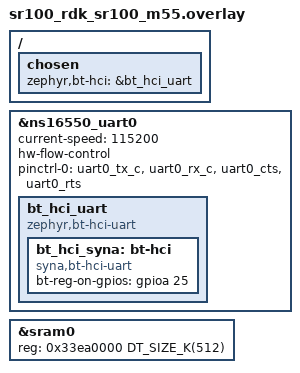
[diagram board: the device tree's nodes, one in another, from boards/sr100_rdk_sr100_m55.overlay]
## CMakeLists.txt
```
# Copyright (c) 2026 Synaptics Incorporated
#
# SPDX-License-Identifier: Apache-2.0

cmake_minimum_required(VERSION 3.20.0)

set(LIBSBC_MODULE_PATH "$ENV{ZEPHYR_BASE}/../modules/lib/libsbc")
if(EXISTS "${LIBSBC_MODULE_PATH}/zephyr/module.yml")
  list(APPEND ZEPHYR_EXTRA_MODULES "${LIBSBC_MODULE_PATH}")
endif()

find_package(Zephyr REQUIRED HINTS $ENV{ZEPHYR_BASE})
project(classic_a2dp_sink)

target_sources(app PRIVATE
  src/main.c
)
```

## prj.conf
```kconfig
CONFIG_BT=y
CONFIG_LOG=y
CONFIG_BT_CLASSIC=y
CONFIG_BT_AVDTP=y
CONFIG_BT_A2DP=y
CONFIG_BT_A2DP_SINK=y
CONFIG_LIBSBC=y
CONFIG_BT_CONN_TX_MAX=15
CONFIG_BT_DEVICE_NAME="SR110 A2DP Sink"
CONFIG_BT_COD=0x200404
CONFIG_BT_DID=y
CONFIG_BT_DEVICE_VEDNOR_ID=0x0000
CONFIG_BT_DEVICE_PRODUCT_ID=0x0001
CONFIG_BT_DEVICE_VERSION=0x0001
CONFIG_BT_BUF_ACL_RX_SIZE=1024

# SR110 + SYNA hardware
CONFIG_BT_H4=y
CONFIG_BT_HCI_SYNA=y
CONFIG_BT_HCI_SYNA_BAUD_RATE=1500000
CONFIG_GPIO=y
CONFIG_UART_INTERRUPT_DRIVEN=y
CONFIG_UART_NS16550_VARIANT_NS16750=y
CONFIG_SRAM_SIZE=512
CONFIG_MAIN_STACK_SIZE=3072
CONFIG_BT_RX_STACK_SIZE=3072
CONFIG_BT_BUF_CMD_TX_SIZE=255
CONFIG_BT_AVDTP_LOG_LEVEL_DBG=y
CONFIG_BT_A2DP_LOG_LEVEL_DBG=y
CONFIG_BT_L2CAP_LOG_LEVEL_DBG=y
CONFIG_BT_SDP_LOG_LEVEL_DBG=y
CONFIG_BT_CONN_LOG_LEVEL_INF=y
CONFIG_BT_HCI_ACL_FLOW_CONTROL=n
CONFIG_BT_HCI_CORE_LOG_LEVEL_INF=y
CONFIG_LOG_PRINTK=n

# Disable unsupported features
CONFIG_SHELL=n
CONFIG_MBEDTLS_PSA_CRYPTO_C=n
CONFIG_XIP=n
```

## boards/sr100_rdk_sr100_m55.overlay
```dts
/*
 * Copyright (c) 2026 Synaptics Incorporated
 *
 * SPDX-License-Identifier: Apache-2.0
 */

/ {
	chosen {
		zephyr,bt-hci = &bt_hci_uart;
	};
};

&ns16550_uart0 {
	status = "okay";
	current-speed = <115200>;
	hw-flow-control;
	pinctrl-0 = <&uart0_tx_c &uart0_rx_c &uart0_cts &uart0_rts>;
	pinctrl-names = "default";

	bt_hci_uart: bt_hci_uart {
		compatible = "zephyr,bt-hci-uart";
		status = "okay";

		bt_hci_syna: bt-hci {
			compatible = "syna,bt-hci-uart";
			status = "okay";
			bt-reg-on-gpios = <&gpioa 25 GPIO_ACTIVE_HIGH>;
		};
	};
};

/* Extend SRAM for BT host stack + patchram (512K needed for Classic BT + A2DP) */
&sram0 {
	reg = <0x33ea0000 DT_SIZE_K(512)>;
	ranges = <0x0 0x33ea0000 DT_SIZE_K(512)>;
};
```

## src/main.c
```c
/*
 * Copyright (c) 2026 Synaptics Incorporated
 *
 * SPDX-License-Identifier: Apache-2.0
 */

#include <zephyr/kernel.h>
#include <zephyr/bluetooth/bluetooth.h>
#include <zephyr/bluetooth/addr.h>
#include <zephyr/bluetooth/conn.h>
#include <zephyr/bluetooth/classic/classic.h>
#include <zephyr/bluetooth/classic/a2dp.h>
#include <zephyr/bluetooth/classic/a2dp_codec_sbc.h>
#include <zephyr/bluetooth/classic/sdp.h>
#include <zephyr/logging/log.h>

LOG_MODULE_REGISTER(a2dp_sink);

#define A2DP_VERSION 0x0103

static struct bt_a2dp *default_a2dp;
BT_A2DP_SBC_SINK_EP_DEFAULT(sbc_sink_ep);
static struct bt_a2dp_stream sbc_stream;

static struct bt_sdp_attribute a2dp_sink_attrs[] = {
	BT_SDP_NEW_SERVICE,
	BT_SDP_LIST(
		BT_SDP_ATTR_SVCLASS_ID_LIST,
		BT_SDP_TYPE_SIZE_VAR(BT_SDP_SEQ8, 3),
		BT_SDP_DATA_ELEM_LIST({
			BT_SDP_TYPE_SIZE(BT_SDP_UUID16),
			BT_SDP_ARRAY_16(BT_SDP_AUDIO_SINK_SVCLASS)
		}, )
	),
	BT_SDP_LIST(
		BT_SDP_ATTR_PROFILE_DESC_LIST,
		BT_SDP_TYPE_SIZE_VAR(BT_SDP_SEQ8, 8),
		BT_SDP_DATA_ELEM_LIST({
			BT_SDP_TYPE_SIZE_VAR(BT_SDP_SEQ8, 6),
			BT_SDP_DATA_ELEM_LIST({
				BT_SDP_TYPE_SIZE(BT_SDP_UUID16),
				BT_SDP_ARRAY_16(BT_SDP_ADVANCED_AUDIO_SVCLASS)
			},
			{
				BT_SDP_TYPE_SIZE(BT_SDP_UINT16),
				BT_SDP_ARRAY_16(A2DP_VERSION)
			}, )
		}, )
	),
	BT_SDP_SUPPORTED_FEATURES(0x0001U),
};

static struct bt_sdp_record a2dp_sink_rec = BT_SDP_RECORD(a2dp_sink_attrs);

static const char *br_addr_str(struct bt_conn *conn, char *buf, size_t len)
{
	const bt_addr_t *addr = bt_conn_get_dst_br(conn);

	if (addr == NULL) {
		snprintk(buf, len, "<unknown>");
		return buf;
	}

	(void)bt_addr_to_str(addr, buf, len);
	return buf;
}

static void sbc_stream_configured(struct bt_a2dp_stream *stream)
{
	ARG_UNUSED(stream);
	LOG_INF("A2DP stream configured");
}

static void sbc_stream_established(struct bt_a2dp_stream *stream)
{
	ARG_UNUSED(stream);
	LOG_INF("A2DP stream established");
}

static void sbc_stream_released(struct bt_a2dp_stream *stream)
{
	ARG_UNUSED(stream);
	LOG_INF("A2DP stream released");
}

static void sbc_stream_started(struct bt_a2dp_stream *stream)
{
	ARG_UNUSED(stream);
	LOG_INF("A2DP stream started - receiving audio data");
}

static void sbc_stream_suspended(struct bt_a2dp_stream *stream)
{
	ARG_UNUSED(stream);
	LOG_INF("A2DP stream suspended");
}

static void sbc_stream_recv(struct bt_a2dp_stream *stream, struct net_buf *buf, uint16_t seq_num,
			    uint32_t ts)
{
	ARG_UNUSED(stream);
	ARG_UNUSED(seq_num);
	ARG_UNUSED(ts);

	LOG_DBG("Received SBC frame: %d bytes, seq=%u, ts=%u", buf->len, seq_num, ts);
	net_buf_pull(buf, buf->len);
}

static struct bt_a2dp_stream_ops stream_ops = {
	.configured = sbc_stream_configured,
	.established = sbc_stream_established,
	.released = sbc_stream_released,
	.started = sbc_stream_started,
	.suspended = sbc_stream_suspended,
	.recv = sbc_stream_recv,
};

static void app_a2dp_connected(struct bt_a2dp *a2dp, int err)
{
	if (err == 0) {
		default_a2dp = a2dp;
		LOG_INF("A2DP signaling connected - waiting for Source to initiate stream");
	} else {
		LOG_WRN("A2DP signaling connect failed (%d)", err);
	}
}

static void app_a2dp_disconnected(struct bt_a2dp *a2dp)
{
	ARG_UNUSED(a2dp);
	default_a2dp = NULL;
	LOG_INF("A2DP signaling disconnected");
}

static int app_a2dp_config_req(struct bt_a2dp *a2dp, struct bt_a2dp_ep *ep,
			       struct bt_a2dp_codec_cfg *codec_cfg, struct bt_a2dp_stream **stream,
			       uint8_t *rsp_err_code)
{
	ARG_UNUSED(a2dp);
	ARG_UNUSED(ep);
	ARG_UNUSED(codec_cfg);

	bt_a2dp_stream_cb_register(&sbc_stream, &stream_ops);
	*stream = &sbc_stream;
	*rsp_err_code = 0;
	LOG_INF("A2DP config request accepted");

	return 0;
}

static int app_a2dp_establish_req(struct bt_a2dp_stream *stream, uint8_t *rsp_err_code)
{
	ARG_UNUSED(stream);
	*rsp_err_code = 0;
	LOG_INF("A2DP establish request accepted");
	return 0;
}

static int app_a2dp_start_req(struct bt_a2dp_stream *stream, uint8_t *rsp_err_code)
{
	ARG_UNUSED(stream);
	*rsp_err_code = 0;
	LOG_INF("A2DP start request accepted");
	return 0;
}

static int app_a2dp_suspend_req(struct bt_a2dp_stream *stream, uint8_t *rsp_err_code)
{
	ARG_UNUSED(stream);
	*rsp_err_code = 0;
	LOG_INF("A2DP suspend request accepted");
	return 0;
}

static int app_a2dp_release_req(struct bt_a2dp_stream *stream, uint8_t *rsp_err_code)
{
	ARG_UNUSED(stream);
	*rsp_err_code = 0;
	LOG_INF("A2DP release request accepted");
	return 0;
}

static int app_a2dp_abort_req(struct bt_a2dp_stream *stream, uint8_t *rsp_err_code)
{
	ARG_UNUSED(stream);
	*rsp_err_code = 0;
	LOG_INF("A2DP abort request accepted");
	return 0;
}

static void app_a2dp_config_rsp(struct bt_a2dp_stream *stream, uint8_t rsp_err_code)
{
	ARG_UNUSED(stream);
	LOG_INF("A2DP config response err=0x%02x", rsp_err_code);
}

static void app_a2dp_establish_rsp(struct bt_a2dp_stream *stream, uint8_t rsp_err_code)
{
	ARG_UNUSED(stream);
	LOG_INF("A2DP establish response err=0x%02x", rsp_err_code);
}

static void app_a2dp_start_rsp(struct bt_a2dp_stream *stream, uint8_t rsp_err_code)
{
	ARG_UNUSED(stream);
	LOG_INF("A2DP start response err=0x%02x", rsp_err_code);
}

static void app_a2dp_suspend_rsp(struct bt_a2dp_stream *stream, uint8_t rsp_err_code)
{
	ARG_UNUSED(stream);
	LOG_INF("A2DP suspend response err=0x%02x", rsp_err_code);
}

static void app_a2dp_release_rsp(struct bt_a2dp_stream *stream, uint8_t rsp_err_code)
{
	ARG_UNUSED(stream);
	LOG_INF("A2DP release response err=0x%02x", rsp_err_code);
}

static void app_a2dp_abort_rsp(struct bt_a2dp_stream *stream, uint8_t rsp_err_code)
{
	ARG_UNUSED(stream);
	LOG_INF("A2DP abort response err=0x%02x", rsp_err_code);
}

static struct bt_a2dp_cb a2dp_cb = {
	.connected = app_a2dp_connected,
	.disconnected = app_a2dp_disconnected,
	.config_req = app_a2dp_config_req,
	.establish_req = app_a2dp_establish_req,
	.start_req = app_a2dp_start_req,
	.suspend_req = app_a2dp_suspend_req,
	.release_req = app_a2dp_release_req,
	.abort_req = app_a2dp_abort_req,
	.config_rsp = app_a2dp_config_rsp,
	.establish_rsp = app_a2dp_establish_rsp,
	.start_rsp = app_a2dp_start_rsp,
	.suspend_rsp = app_a2dp_suspend_rsp,
	.release_rsp = app_a2dp_release_rsp,
	.abort_rsp = app_a2dp_abort_rsp,
};

static void br_conn_connected(struct bt_conn *conn, uint8_t err)
{
	char addr[BT_ADDR_STR_LEN];

	if (!bt_conn_is_type(conn, BT_CONN_TYPE_BR)) {
		return;
	}

	if (err != 0U) {
		LOG_WRN("BR/EDR ACL connect failed (%u), peer %s", err,
			br_addr_str(conn, addr, sizeof(addr)));
		return;
	}

	LOG_INF("BR/EDR ACL connected: %s", br_addr_str(conn, addr, sizeof(addr)));
}

static void br_conn_disconnected(struct bt_conn *conn, uint8_t reason)
{
	char addr[BT_ADDR_STR_LEN];

	if (!bt_conn_is_type(conn, BT_CONN_TYPE_BR)) {
		return;
	}

	LOG_INF("BR/EDR ACL disconnected: %s (reason 0x%02x)",
		br_addr_str(conn, addr, sizeof(addr)), reason);
}

static void br_conn_security_changed(struct bt_conn *conn, bt_security_t level,
				     enum bt_security_err err)
{
	char addr[BT_ADDR_STR_LEN];

	if (!bt_conn_is_type(conn, BT_CONN_TYPE_BR)) {
		return;
	}

	LOG_INF("BR/EDR security changed: %s level %u err %d",
		br_addr_str(conn, addr, sizeof(addr)), level, err);

	LOG_INF("Waiting for A2DP Source to initiate AVDTP signaling");
}

static struct bt_conn_cb conn_cb = {
	.connected = br_conn_connected,
	.disconnected = br_conn_disconnected,
	.security_changed = br_conn_security_changed,
};

static void auth_pairing_complete(struct bt_conn *conn, bool bonded)
{
	char addr[BT_ADDR_STR_LEN];

	if (!bt_conn_is_type(conn, BT_CONN_TYPE_BR)) {
		return;
	}

	LOG_INF("Pairing complete: %s bonded=%d", br_addr_str(conn, addr, sizeof(addr)), bonded);
}

static void auth_pairing_failed(struct bt_conn *conn, enum bt_security_err reason)
{
	char addr[BT_ADDR_STR_LEN];

	if (!bt_conn_is_type(conn, BT_CONN_TYPE_BR)) {
		return;
	}

	LOG_WRN("Pairing failed: %s reason=%d", br_addr_str(conn, addr, sizeof(addr)), reason);
}

static struct bt_conn_auth_info_cb auth_info_cb = {
	.pairing_complete = auth_pairing_complete,
	.pairing_failed = auth_pairing_failed,
};

static int bt_ready(void)
{
	int err;

	err = bt_enable(NULL);
	if (err) {
		LOG_ERR("Bluetooth init failed (err %d)", err);
		return err;
	}

	LOG_INF("Bluetooth enabled");

	{
		bt_addr_le_t addrs[CONFIG_BT_ID_MAX];
		size_t count = ARRAY_SIZE(addrs);
		char addr_str[BT_ADDR_LE_STR_LEN];

		bt_id_get(addrs, &count);
		if (count > 0) {
			bt_addr_le_to_str(&addrs[0], addr_str, sizeof(addr_str));
			LOG_INF("Local BD_ADDR: %s", addr_str);
		}
	}

	bt_conn_cb_register(&conn_cb);
	bt_conn_auth_info_cb_register(&auth_info_cb);
	LOG_INF("Connection diagnostic callbacks registered");

	bt_sdp_register_service(&a2dp_sink_rec);
	LOG_INF("A2DP SDP record registered");

	err = bt_a2dp_register_ep(&sbc_sink_ep, BT_AVDTP_AUDIO, BT_AVDTP_SINK);
	if (err) {
		LOG_ERR("A2DP endpoint register failed (err %d)", err);
		return err;
	}

	err = bt_a2dp_register_cb(&a2dp_cb);
	if (err) {
		LOG_ERR("A2DP callback register failed (err %d)", err);
		return err;
	}

	LOG_INF("A2DP sink endpoint registered");

	err = bt_br_set_connectable(true, NULL);
	if (err) {
		LOG_ERR("Failed to enable BR/EDR connectable (err %d)", err);
		return err;
	}

	err = bt_br_set_discoverable(true, false);
	if (err) {
		LOG_ERR("Failed to enable BR/EDR discoverable (err %d)", err);
		return err;
	}

	LOG_INF("BR/EDR inquiry/page scan enabled");
	return 0;
}

int main(void)
{
	int err;

	LOG_INF("Starting Classic A2DP Sink Sample for SR110");

	err = bt_ready();
	if (err) {
		return err;
	}

	LOG_INF("Waiting for A2DP Source connection...");
	while (1) {
		k_sleep(K_SECONDS(10));
	}

	return 0;
}
```
